# 702 register map
Vendor: bouffalolab; Series: WiFi BT
CPU: 702, little endian
Registers are 32-bit, read-write, reset 0x0 unless marked. A register's access mark holds for its fields unless they carry their own. Offsets are from the block's base; [hi:lo] are bit positions; {n}, {i} and the like mark numbered series.

## mjpeg
Base 0x4000AE00
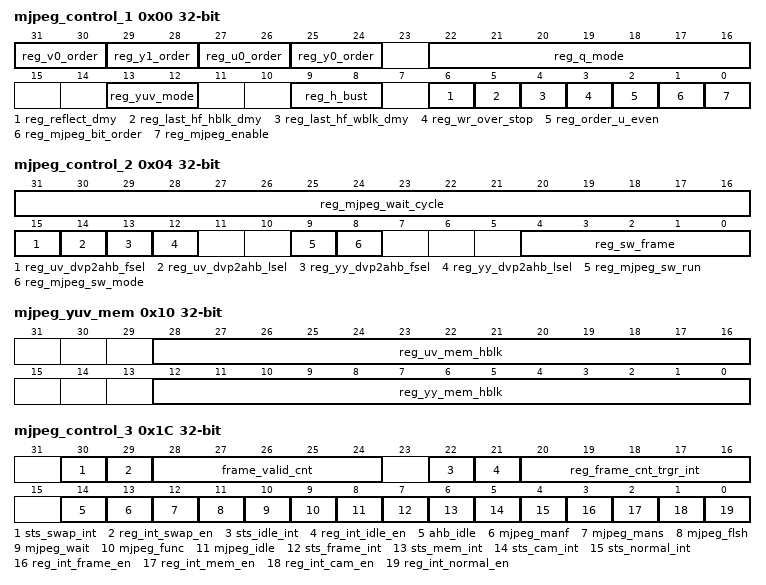
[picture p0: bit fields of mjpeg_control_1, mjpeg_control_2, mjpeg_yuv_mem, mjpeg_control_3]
0x00 mjpeg_control_1
  [31:30] reg_v0_order, [29:28] reg_y1_order, [27:26] reg_u0_order, [25:24] reg_y0_order, [22:16] reg_q_mode, [13:12] reg_yuv_mode, [9:8] reg_h_bust, [6] reg_reflect_dmy, [5] reg_last_hf_hblk_dmy, [4] reg_last_hf_wblk_dmy, [3] reg_wr_over_stop, [2] reg_order_u_even, [1] reg_mjpeg_bit_order, [0] reg_mjpeg_enable
0x04 mjpeg_control_2
  [31:16] reg_mjpeg_wait_cycle, [15] reg_uv_dvp2ahb_fsel, [14] reg_uv_dvp2ahb_lsel, [13] reg_yy_dvp2ahb_fsel, [12] reg_yy_dvp2ahb_lsel, [9] reg_mjpeg_sw_run, [8] reg_mjpeg_sw_mode, [4:0] reg_sw_frame
0x08 mjpeg_yy_frame_addr
  [31:0] reg_yy_addr_start
0x0C mjpeg_uv_frame_addr
  [31:0] reg_uv_addr_start
0x10 mjpeg_yuv_mem
  [28:16] reg_uv_mem_hblk, [12:0] reg_yy_mem_hblk
0x14 jpeg_frame_addr
  [31:0] reg_w_addr_start
0x18 jpeg_store_memory
  [31:0] reg_w_burst_cnt
0x1C mjpeg_control_3
  [30] sts_swap_int, [29] reg_int_swap_en, [28:24] frame_valid_cnt, [22] sts_idle_int, [21] reg_int_idle_en, [20:16] reg_frame_cnt_trgr_int, [14] ahb_idle, [13] mjpeg_manf, [12] mjpeg_mans, [11] mjpeg_flsh, [10] mjpeg_wait, [9] mjpeg_func, [8] mjpeg_idle, [7] sts_frame_int, [6] sts_mem_int, [5] sts_cam_int, [4] sts_normal_int, [3] reg_int_frame_en, [2] reg_int_mem_en, [1] reg_int_cam_en, [0] reg_int_normal_en
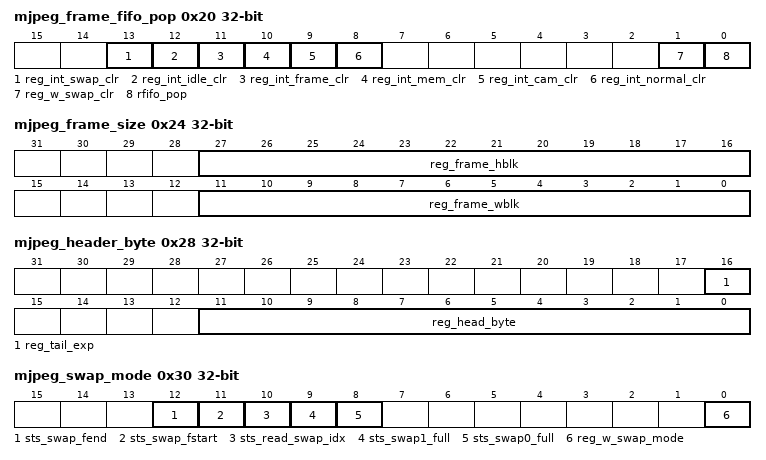
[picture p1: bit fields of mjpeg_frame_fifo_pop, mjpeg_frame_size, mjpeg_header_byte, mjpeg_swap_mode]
0x20 mjpeg_frame_fifo_pop
  [13] reg_int_swap_clr, [12] reg_int_idle_clr, [11] reg_int_frame_clr, [10] reg_int_mem_clr, [9] reg_int_cam_clr, [8] reg_int_normal_clr, [1] reg_w_swap_clr, [0] rfifo_pop
0x24 mjpeg_frame_size
  [27:16] reg_frame_hblk, [11:0] reg_frame_wblk
0x28 mjpeg_header_byte
  [16] reg_tail_exp, [11:0] reg_head_byte
0x30 mjpeg_swap_mode
  [12] sts_swap_fend, [11] sts_swap_fstart, [10] sts_read_swap_idx, [9] sts_swap1_full, [8] sts_swap0_full, [0] reg_w_swap_mode
0x34 mjpeg_swap_bit_cnt
  [31:0] frame_swap_end_bit_cnt
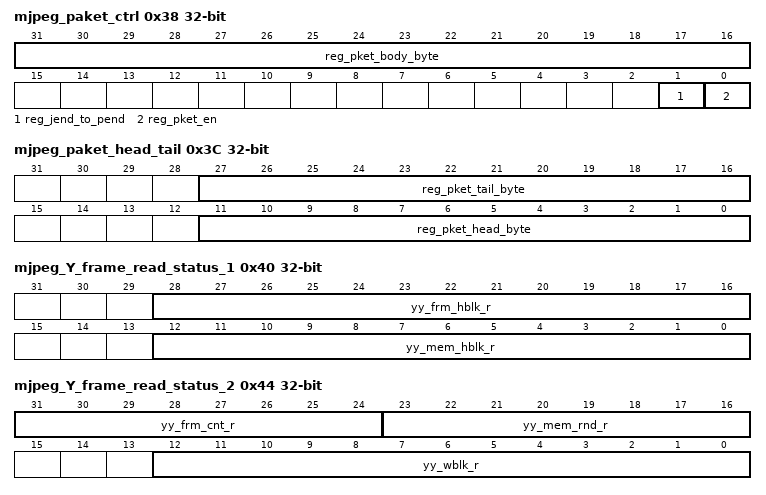
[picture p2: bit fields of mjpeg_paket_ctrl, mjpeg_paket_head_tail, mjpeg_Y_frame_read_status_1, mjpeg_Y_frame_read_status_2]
0x38 mjpeg_paket_ctrl
  [31:16] reg_pket_body_byte, [1] reg_jend_to_pend, [0] reg_pket_en
0x3C mjpeg_paket_head_tail
  [27:16] reg_pket_tail_byte, [11:0] reg_pket_head_byte
0x40 mjpeg_Y_frame_read_status_1
  [28:16] yy_frm_hblk_r, [12:0] yy_mem_hblk_r
0x44 mjpeg_Y_frame_read_status_2
  [31:24] yy_frm_cnt_r, [23:16] yy_mem_rnd_r, [12:0] yy_wblk_r
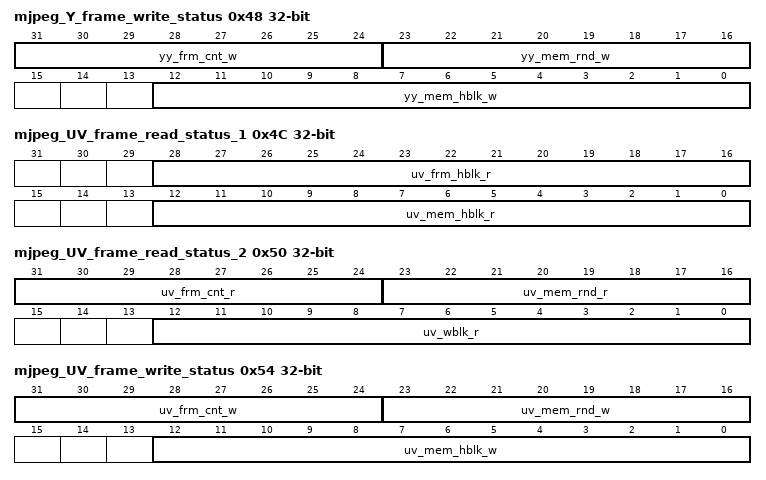
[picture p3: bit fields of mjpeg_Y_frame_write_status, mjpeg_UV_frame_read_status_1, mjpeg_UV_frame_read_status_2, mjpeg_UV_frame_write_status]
0x48 mjpeg_Y_frame_write_status
  [31:24] yy_frm_cnt_w, [23:16] yy_mem_rnd_w, [12:0] yy_mem_hblk_w
0x4C mjpeg_UV_frame_read_status_1
  [28:16] uv_frm_hblk_r, [12:0] uv_mem_hblk_r
0x50 mjpeg_UV_frame_read_status_2
  [31:24] uv_frm_cnt_r, [23:16] uv_mem_rnd_r, [12:0] uv_wblk_r
0x54 mjpeg_UV_frame_write_status
  [31:24] uv_frm_cnt_w, [23:16] uv_mem_rnd_w, [12:0] uv_mem_hblk_w
{0x80+8i} mjpeg_start_addr{i} (i=0..7)
  [31:0] frame_start_addr_{i}
{0x84+8i} mjpeg_bit_cnt{i} (i=0..7)
  [31:0] frame_bit_cnt_{i}
0xC0 mjpeg_start_addr_8
  [31:0] frame_start_addr_8
0xC4 mjpeg_bit_cnt_8
  [31:0] frame_bit_cnt_8
0xC8 mjpeg_start_addr_9
  [31:0] frame_start_addr_9
0xCC mjpeg_bit_cnt_9
  [31:0] frame_bit_cnt_9
0xD0 mjpeg_start_addr_a
  [31:0] frame_start_addr_a
0xD4 mjpeg_bit_cnt_a
  [31:0] frame_bit_cnt_a
0xD8 mjpeg_start_addr_b
  [31:0] frame_start_addr_b
0xDC mjpeg_bit_cnt_b
  [31:0] frame_bit_cnt_b
0xE0 mjpeg_start_addr_c
  [31:0] frame_start_addr_c
0xE4 mjpeg_bit_cnt_c
  [31:0] frame_bit_cnt_c
0xE8 mjpeg_start_addr_d
  [31:0] frame_start_addr_d
0xEC mjpeg_bit_cnt_d
  [31:0] frame_bit_cnt_d
0xF0 mjpeg_start_addr_e
  [31:0] frame_start_addr_e
0xF4 mjpeg_bit_cnt_e
  [31:0] frame_bit_cnt_e
0xF8 mjpeg_start_addr_f
  [31:0] frame_start_addr_f
0xFC mjpeg_bit_cnt_f
  [31:0] frame_bit_cnt_f
{0x100+4i} mjpeg_q_mode{i} (i=0..7)
  [6:0] frame_q_mode_{i}
0x120 mjpeg_q_mode_8
  [6:0] frame_q_mode_8
0x124 mjpeg_q_mode_9
  [6:0] frame_q_mode_9
0x128 mjpeg_q_mode_a
  [6:0] frame_q_mode_a
0x12C mjpeg_q_mode_b
  [6:0] frame_q_mode_b
0x130 mjpeg_q_mode_c
  [6:0] frame_q_mode_c
0x134 mjpeg_q_mode_d
  [6:0] frame_q_mode_d
0x138 mjpeg_q_mode_e
  [6:0] frame_q_mode_e
0x13C mjpeg_q_mode_f
  [6:0] frame_q_mode_f
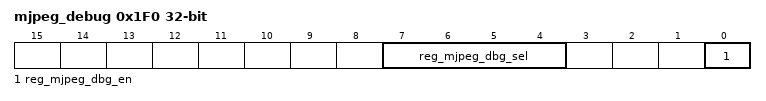
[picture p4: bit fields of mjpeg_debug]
0x1F0 mjpeg_debug
  [7:4] reg_mjpeg_dbg_sel, [0] reg_mjpeg_dbg_en
0x1FC mjpeg_dummy_reg
